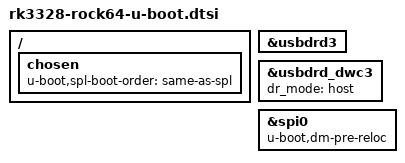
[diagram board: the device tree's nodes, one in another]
// SPDX-License-Identifier: GPL-2.0+
/*
 * (C) Copyright 2018-2019 Rockchip Electronics Co., Ltd
 */

#include "rk3328-u-boot.dtsi"
#include "rk3328-sdram-lpddr3-1600.dtsi"
/ {
	chosen {
		u-boot,spl-boot-order = "same-as-spl", &sdmmc, &emmc;
	};
};

&usbdrd3 {
	status = "okay";
};

&usbdrd_dwc3 {
	status = "okay";
	dr_mode = "host";
};

&spi0 {
	u-boot,dm-pre-reloc;
};
